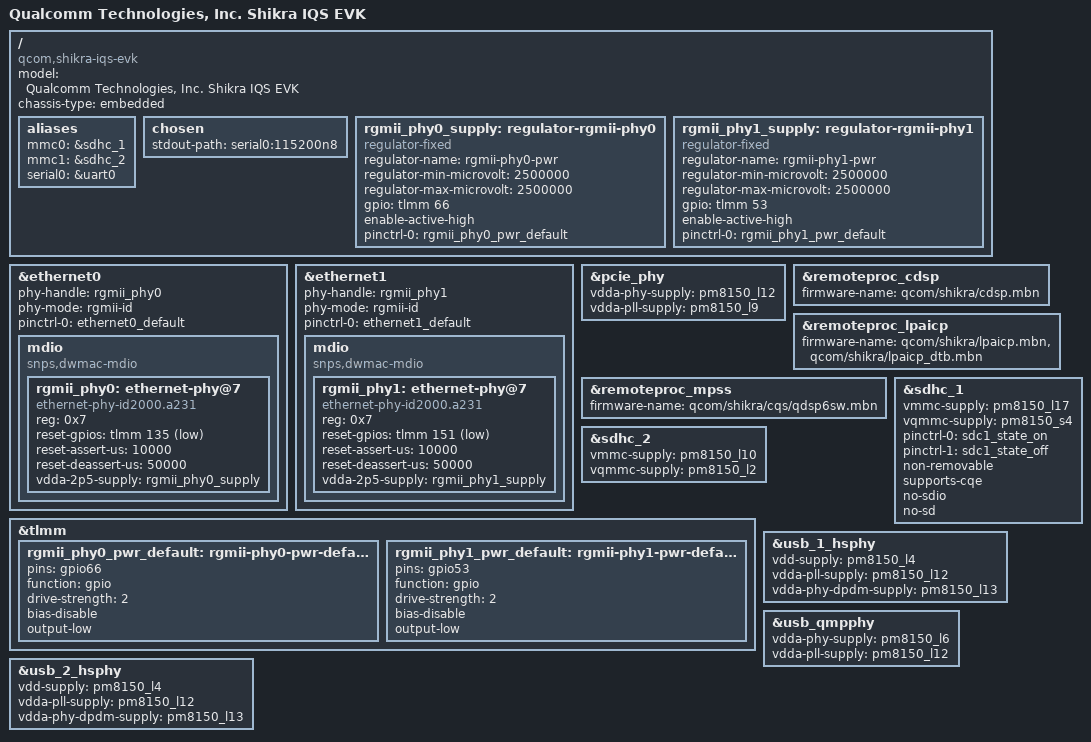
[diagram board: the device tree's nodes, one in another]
// SPDX-License-Identifier: BSD-3-Clause
/*
 * Copyright (c) Qualcomm Technologies, Inc. and/or its subsidiaries.
 */

/dts-v1/;

#include "shikra-iqs-som.dtsi"
#include "shikra-evk.dtsi"

/ {
	model = "Qualcomm Technologies, Inc. Shikra IQS EVK";
	compatible = "qcom,shikra-iqs-evk", "qcom,shikra-iqs-som", "qcom,shikra";
	chassis-type = "embedded";

	aliases {
		mmc0 = &sdhc_1;
		mmc1 = &sdhc_2; /* SDC2 SD card slot */
		serial0 = &uart0;
	};

	chosen {
		stdout-path = "serial0:115200n8";
	};

	rgmii_phy0_supply: regulator-rgmii-phy0 {
		compatible = "regulator-fixed";
		regulator-name = "rgmii-phy0-pwr";
		regulator-min-microvolt = <2500000>;
		regulator-max-microvolt = <2500000>;
		gpio = <&tlmm 66 GPIO_ACTIVE_HIGH>;
		enable-active-high;
		pinctrl-0 = <&rgmii_phy0_pwr_default>;
		pinctrl-names = "default";
	};

	rgmii_phy1_supply: regulator-rgmii-phy1 {
		compatible = "regulator-fixed";
		regulator-name = "rgmii-phy1-pwr";
		regulator-min-microvolt = <2500000>;
		regulator-max-microvolt = <2500000>;
		gpio = <&tlmm 53 GPIO_ACTIVE_HIGH>;
		enable-active-high;
		pinctrl-0 = <&rgmii_phy1_pwr_default>;
		pinctrl-names = "default";
	};
};

&ethernet0 {
	phy-handle = <&rgmii_phy0>;
	phy-mode = "rgmii-id";

	pinctrl-0 = <&ethernet0_default>;
	pinctrl-names = "default";

	status = "okay";

	mdio {
		compatible = "snps,dwmac-mdio";
		#address-cells = <1>;
		#size-cells = <0>;

		rgmii_phy0: ethernet-phy@7 {
			compatible = "ethernet-phy-id2000.a231";
			reg = <0x7>;
			reset-gpios = <&tlmm 135 GPIO_ACTIVE_LOW>;
			reset-assert-us = <10000>;
			reset-deassert-us = <50000>;
			vdda-2p5-supply = <&rgmii_phy0_supply>;
		};
	};
};

&ethernet1 {
	phy-handle = <&rgmii_phy1>;
	phy-mode = "rgmii-id";

	pinctrl-0 = <&ethernet1_default>;
	pinctrl-names = "default";

	status = "okay";

	mdio {
		compatible = "snps,dwmac-mdio";
		#address-cells = <1>;
		#size-cells = <0>;

		rgmii_phy1: ethernet-phy@7 {
			compatible = "ethernet-phy-id2000.a231";
			reg = <0x7>;
			reset-gpios = <&tlmm 151 GPIO_ACTIVE_LOW>;
			reset-assert-us = <10000>;
			reset-deassert-us = <50000>;
			vdda-2p5-supply = <&rgmii_phy1_supply>;
		};
	};
};

&pcie_phy {
	vdda-phy-supply = <&pm8150_l12>;
	vdda-pll-supply = <&pm8150_l9>;

	status = "okay";
};

&remoteproc_cdsp {
	firmware-name = "qcom/shikra/cdsp.mbn";

	status = "okay";
};

&remoteproc_lpaicp {
	firmware-name = "qcom/shikra/lpaicp.mbn",
			"qcom/shikra/lpaicp_dtb.mbn";

	status = "okay";
};

&remoteproc_mpss {
	firmware-name = "qcom/shikra/cqs/qdsp6sw.mbn";

	status = "okay";
};

&sdhc_1 {
	vmmc-supply = <&pm8150_l17>;
	vqmmc-supply = <&pm8150_s4>;

	pinctrl-0 = <&sdc1_state_on>;
	pinctrl-1 = <&sdc1_state_off>;
	pinctrl-names = "default", "sleep";

	non-removable;
	supports-cqe;
	no-sdio;
	no-sd;

	status = "okay";
};

&sdhc_2 {
	vmmc-supply = <&pm8150_l10>;
	vqmmc-supply = <&pm8150_l2>;

	status = "okay";
};

&tlmm {
	rgmii_phy0_pwr_default: rgmii-phy0-pwr-default-state {
		pins = "gpio66";
		function = "gpio";
		drive-strength = <2>;
		bias-disable;
		output-low;
	};

	rgmii_phy1_pwr_default: rgmii-phy1-pwr-default-state {
		pins = "gpio53";
		function = "gpio";
		drive-strength = <2>;
		bias-disable;
		output-low;
	};
};

&usb_1_hsphy {
	vdd-supply = <&pm8150_l4>;
	vdda-pll-supply = <&pm8150_l12>;
	vdda-phy-dpdm-supply = <&pm8150_l13>;

	status = "okay";
};

&usb_qmpphy {
	vdda-phy-supply = <&pm8150_l6>;
	vdda-pll-supply = <&pm8150_l12>;

	status = "okay";
};

&usb_2_hsphy {
	vdd-supply = <&pm8150_l4>;
	vdda-pll-supply = <&pm8150_l12>;
	vdda-phy-dpdm-supply = <&pm8150_l13>;

	status = "okay";
};
